# CBASS_AC_NONSAFE0_QOS register map
Vendor: Texas Instruments
Peripheral module from a debugger description file (folder J721S2).
Registers are 32-bit, read-write, reset 0x7000 unless marked. A register's access mark holds for its fields unless they carry their own. Offsets are as the file gives them; lines under a group give offsets from that group; [hi:lo] are bit positions; {n}, {i} and the like mark numbered series; 'fields as' and 'values as' point back to an identical list; <NAME> marks a mode.

## CBASS_AC_NONSAFE0_QOS
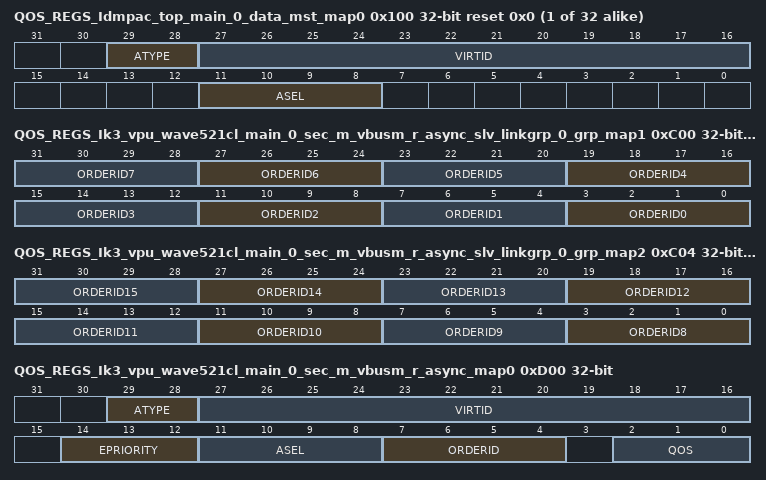
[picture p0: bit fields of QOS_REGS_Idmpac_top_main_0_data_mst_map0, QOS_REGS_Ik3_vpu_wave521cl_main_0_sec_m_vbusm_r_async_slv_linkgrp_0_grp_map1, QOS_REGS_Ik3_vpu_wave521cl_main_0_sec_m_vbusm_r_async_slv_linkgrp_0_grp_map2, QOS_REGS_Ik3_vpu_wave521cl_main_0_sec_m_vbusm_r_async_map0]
{0x100+4i} QOS_REGS_Idmpac_top_main_0_data_mst_map{i} reset 0x0 (i=0..31) — The Map Register defines the fields for the master Idmpac_top_main_0.data_mst per channel.
  [29:28] ATYPE — epriority signal for channel N. 0 = physical. 1 = intermediate. 2 = virtual. 3 = physical with coherence.
  [27:16] VIRTID — virtid signal for channel N.
  [11:8] ASEL — asel signal for channel N. 0 = SOC address. 1-15 = peripheral address.
0xC00 QOS_REGS_Ik3_vpu_wave521cl_main_0_sec_m_vbusm_r_async_slv_linkgrp_0_grp_map1 reset 0x0 — The Group Map Register defines the final orderid for the master Ik3_vpu_wave521cl_main_0.sec_m_vbusm_r_async for group slv_linkgrp_0.
  [4n+3:4n] ORDERID{n} (n=0..7) — orderid signal for {n}.
0xC04 QOS_REGS_Ik3_vpu_wave521cl_main_0_sec_m_vbusm_r_async_slv_linkgrp_0_grp_map2 reset 0x0 — The Group Map Register defines the final orderid for the master Ik3_vpu_wave521cl_main_0.sec_m_vbusm_r_async for group slv_linkgrp_0.
  [4n-29:4n-32] ORDERID{n} (n=8..15) — orderid signal for {n-8}.
0xD00 QOS_REGS_Ik3_vpu_wave521cl_main_0_sec_m_vbusm_r_async_map0 — The Map Register defines the fields for the master Ik3_vpu_wave521cl_main_0.sec_m_vbusm_r_async per channel.
  [29:28] ATYPE — epriority signal for channel N. 0 = physical. 1 = intermediate. 2 = virtual. 3 = physical with coherence.
  [27:16] VIRTID — virtid signal for channel N.
  [14:12] EPRIORITY — epriority signal for channel N.
  [11:8] ASEL — asel signal for channel N. 0 = SOC address. 1-15 = peripheral address.
  [7:4] ORDERID — orderid signal for channel N.
  [2:0] QOS — qos signal for channel N.
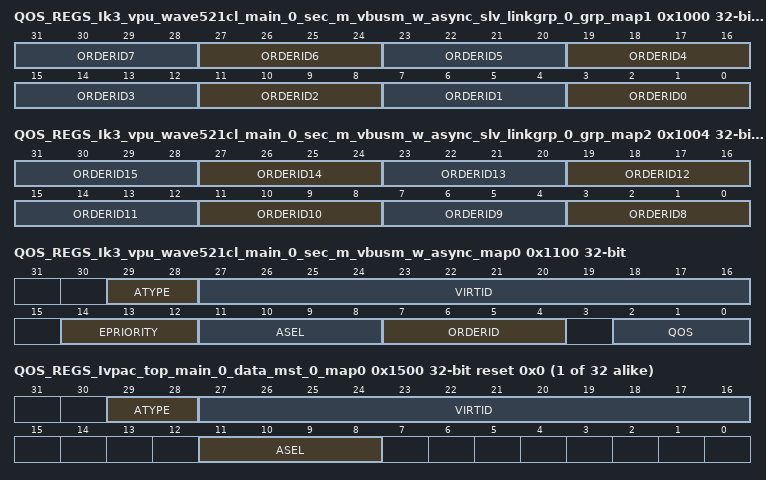
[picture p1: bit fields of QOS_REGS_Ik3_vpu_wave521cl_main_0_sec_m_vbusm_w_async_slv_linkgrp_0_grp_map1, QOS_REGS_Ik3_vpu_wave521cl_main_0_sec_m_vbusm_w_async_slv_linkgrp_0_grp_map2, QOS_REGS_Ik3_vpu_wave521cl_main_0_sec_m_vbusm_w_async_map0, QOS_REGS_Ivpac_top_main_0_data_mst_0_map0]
0x1000 QOS_REGS_Ik3_vpu_wave521cl_main_0_sec_m_vbusm_w_async_slv_linkgrp_0_grp_map1 reset 0x0 — The Group Map Register defines the final orderid for the master Ik3_vpu_wave521cl_main_0.sec_m_vbusm_w_async for group slv_linkgrp_0.
  [4n+3:4n] ORDERID{n} (n=0..7) — orderid signal for {n}.
0x1004 QOS_REGS_Ik3_vpu_wave521cl_main_0_sec_m_vbusm_w_async_slv_linkgrp_0_grp_map2 reset 0x0 — The Group Map Register defines the final orderid for the master Ik3_vpu_wave521cl_main_0.sec_m_vbusm_w_async for group slv_linkgrp_0.
  [4n-29:4n-32] ORDERID{n} (n=8..15) — orderid signal for {n-8}.
0x1100 QOS_REGS_Ik3_vpu_wave521cl_main_0_sec_m_vbusm_w_async_map0 — The Map Register defines the fields for the master Ik3_vpu_wave521cl_main_0.sec_m_vbusm_w_async per channel.
  fields as QOS_REGS_Ik3_vpu_wave521cl_main_0_sec_m_vbusm_r_async_map0
{0x1500+4i} QOS_REGS_Ivpac_top_main_0_data_mst_0_map{i} reset 0x0 (i=0..31) — The Map Register defines the fields for the master Ivpac_top_main_0.data_mst_0 per channel.
  fields as QOS_REGS_Idmpac_top_main_0_data_mst_map0
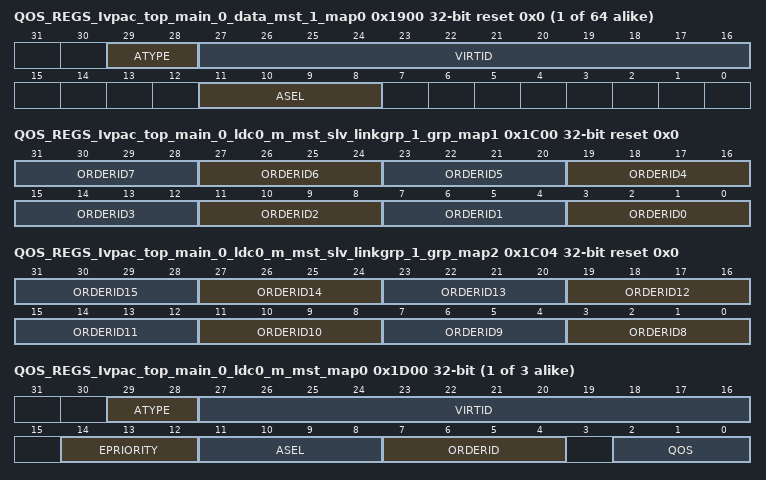
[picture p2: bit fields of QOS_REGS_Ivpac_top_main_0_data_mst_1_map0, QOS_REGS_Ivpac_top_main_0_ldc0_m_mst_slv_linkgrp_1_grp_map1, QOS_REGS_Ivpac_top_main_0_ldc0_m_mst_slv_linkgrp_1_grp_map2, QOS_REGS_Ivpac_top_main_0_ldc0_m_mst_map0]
{0x1900+4i} QOS_REGS_Ivpac_top_main_0_data_mst_1_map{i} reset 0x0 (i=0..63) — The Map Register defines the fields for the master Ivpac_top_main_0.data_mst_1 per channel.
  fields as QOS_REGS_Idmpac_top_main_0_data_mst_map0
0x1C00 QOS_REGS_Ivpac_top_main_0_ldc0_m_mst_slv_linkgrp_1_grp_map1 reset 0x0 — The Group Map Register defines the final orderid for the master Ivpac_top_main_0.ldc0_m_mst for group slv_linkgrp_1.
  [4n+3:4n] ORDERID{n} (n=0..7) — orderid signal for {n}.
0x1C04 QOS_REGS_Ivpac_top_main_0_ldc0_m_mst_slv_linkgrp_1_grp_map2 reset 0x0 — The Group Map Register defines the final orderid for the master Ivpac_top_main_0.ldc0_m_mst for group slv_linkgrp_1.
  [4n-29:4n-32] ORDERID{n} (n=8..15) — orderid signal for {n-8}.
{0x1D00+4i} QOS_REGS_Ivpac_top_main_0_ldc0_m_mst_map{i} (i=0..2) — The Map Register defines the fields for the master Ivpac_top_main_0.ldc0_m_mst per channel.
  fields as QOS_REGS_Ik3_vpu_wave521cl_main_0_sec_m_vbusm_r_async_map0
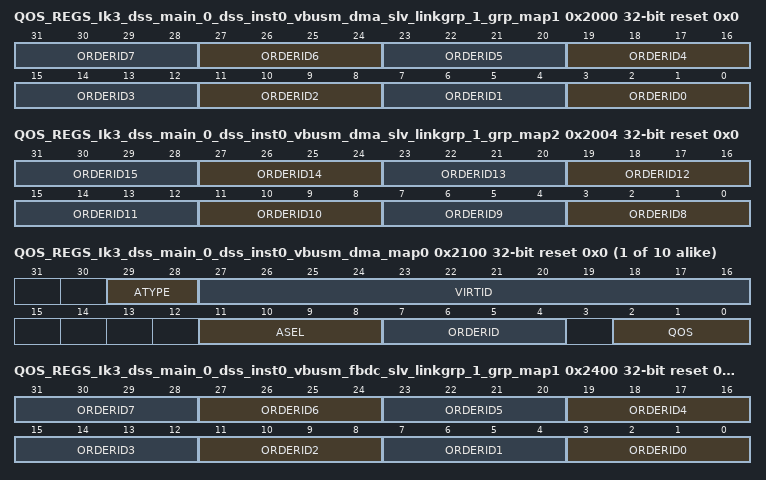
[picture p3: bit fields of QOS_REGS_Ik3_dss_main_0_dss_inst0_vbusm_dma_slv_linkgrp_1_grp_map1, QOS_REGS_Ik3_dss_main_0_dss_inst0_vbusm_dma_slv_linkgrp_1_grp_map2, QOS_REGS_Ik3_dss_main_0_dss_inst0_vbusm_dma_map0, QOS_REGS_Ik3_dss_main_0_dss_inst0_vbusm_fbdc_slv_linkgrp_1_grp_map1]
0x2000 QOS_REGS_Ik3_dss_main_0_dss_inst0_vbusm_dma_slv_linkgrp_1_grp_map1 reset 0x0 — The Group Map Register defines the final orderid for the master Ik3_dss_main_0.dss_inst0_vbusm_dma for group slv_linkgrp_1.
  [4n+3:4n] ORDERID{n} (n=0..7) — orderid signal for {n}.
0x2004 QOS_REGS_Ik3_dss_main_0_dss_inst0_vbusm_dma_slv_linkgrp_1_grp_map2 reset 0x0 — The Group Map Register defines the final orderid for the master Ik3_dss_main_0.dss_inst0_vbusm_dma for group slv_linkgrp_1.
  [4n-29:4n-32] ORDERID{n} (n=8..15) — orderid signal for {n-8}.
{0x2100+4i} QOS_REGS_Ik3_dss_main_0_dss_inst0_vbusm_dma_map{i} reset 0x0 (i=0..9) — The Map Register defines the fields for the master Ik3_dss_main_0.dss_inst0_vbusm_dma per channel.
  [29:28] ATYPE — epriority signal for channel N. 0 = physical. 1 = intermediate. 2 = virtual. 3 = physical with coherence.
  [27:16] VIRTID — virtid signal for channel N.
  [11:8] ASEL — asel signal for channel N. 0 = SOC address. 1-15 = peripheral address.
  [7:4] ORDERID — orderid signal for channel N.
  [2:0] QOS — qos signal for channel N.
0x2400 QOS_REGS_Ik3_dss_main_0_dss_inst0_vbusm_fbdc_slv_linkgrp_1_grp_map1 reset 0x0 — The Group Map Register defines the final orderid for the master Ik3_dss_main_0.dss_inst0_vbusm_fbdc for group slv_linkgrp_1.
  [4n+3:4n] ORDERID{n} (n=0..7) — orderid signal for {n}.
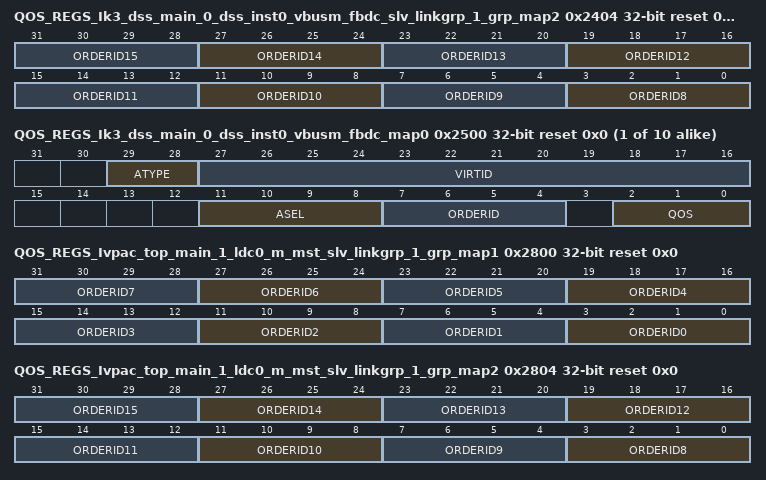
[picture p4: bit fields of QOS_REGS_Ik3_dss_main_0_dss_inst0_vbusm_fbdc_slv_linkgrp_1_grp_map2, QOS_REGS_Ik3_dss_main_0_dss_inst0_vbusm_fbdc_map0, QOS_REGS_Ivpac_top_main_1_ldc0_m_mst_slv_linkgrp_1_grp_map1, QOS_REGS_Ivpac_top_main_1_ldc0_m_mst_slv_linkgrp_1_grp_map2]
0x2404 QOS_REGS_Ik3_dss_main_0_dss_inst0_vbusm_fbdc_slv_linkgrp_1_grp_map2 reset 0x0 — The Group Map Register defines the final orderid for the master Ik3_dss_main_0.dss_inst0_vbusm_fbdc for group slv_linkgrp_1.
  [4n-29:4n-32] ORDERID{n} (n=8..15) — orderid signal for {n-8}.
{0x2500+4i} QOS_REGS_Ik3_dss_main_0_dss_inst0_vbusm_fbdc_map{i} reset 0x0 (i=0..9) — The Map Register defines the fields for the master Ik3_dss_main_0.dss_inst0_vbusm_fbdc per channel.
  fields as QOS_REGS_Ik3_dss_main_0_dss_inst0_vbusm_dma_map0
0x2800 QOS_REGS_Ivpac_top_main_1_ldc0_m_mst_slv_linkgrp_1_grp_map1 reset 0x0 — The Group Map Register defines the final orderid for the master Ivpac_top_main_1.ldc0_m_mst for group slv_linkgrp_1.
  [4n+3:4n] ORDERID{n} (n=0..7) — orderid signal for {n}.
0x2804 QOS_REGS_Ivpac_top_main_1_ldc0_m_mst_slv_linkgrp_1_grp_map2 reset 0x0 — The Group Map Register defines the final orderid for the master Ivpac_top_main_1.ldc0_m_mst for group slv_linkgrp_1.
  [4n-29:4n-32] ORDERID{n} (n=8..15) — orderid signal for {n-8}.
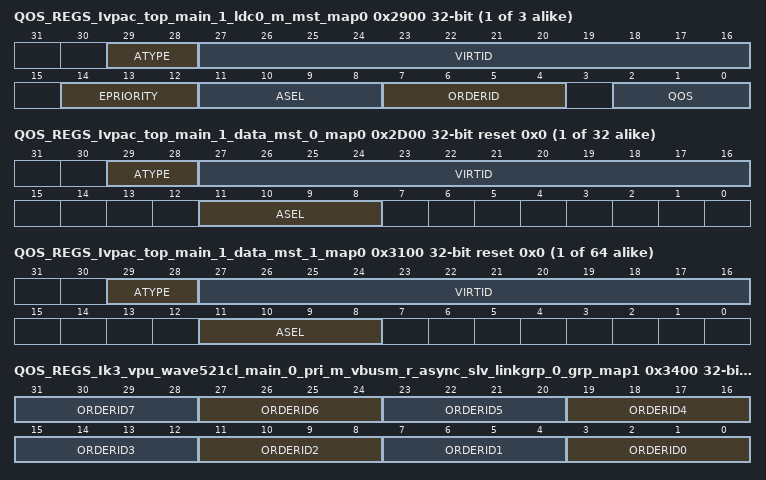
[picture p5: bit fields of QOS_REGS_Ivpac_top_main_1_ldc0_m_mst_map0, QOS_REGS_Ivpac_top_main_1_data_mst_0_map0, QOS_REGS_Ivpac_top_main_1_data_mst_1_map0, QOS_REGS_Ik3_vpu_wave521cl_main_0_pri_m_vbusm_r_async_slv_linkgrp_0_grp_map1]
{0x2900+4i} QOS_REGS_Ivpac_top_main_1_ldc0_m_mst_map{i} (i=0..2) — The Map Register defines the fields for the master Ivpac_top_main_1.ldc0_m_mst per channel.
  fields as QOS_REGS_Ik3_vpu_wave521cl_main_0_sec_m_vbusm_r_async_map0
{0x2D00+4i} QOS_REGS_Ivpac_top_main_1_data_mst_0_map{i} reset 0x0 (i=0..31) — The Map Register defines the fields for the master Ivpac_top_main_1.data_mst_0 per channel.
  fields as QOS_REGS_Idmpac_top_main_0_data_mst_map0
{0x3100+4i} QOS_REGS_Ivpac_top_main_1_data_mst_1_map{i} reset 0x0 (i=0..63) — The Map Register defines the fields for the master Ivpac_top_main_1.data_mst_1 per channel.
  fields as QOS_REGS_Idmpac_top_main_0_data_mst_map0
0x3400 QOS_REGS_Ik3_vpu_wave521cl_main_0_pri_m_vbusm_r_async_slv_linkgrp_0_grp_map1 reset 0x0 — The Group Map Register defines the final orderid for the master Ik3_vpu_wave521cl_main_0.pri_m_vbusm_r_async for group slv_linkgrp_0.
  [4n+3:4n] ORDERID{n} (n=0..7) — orderid signal for {n}.
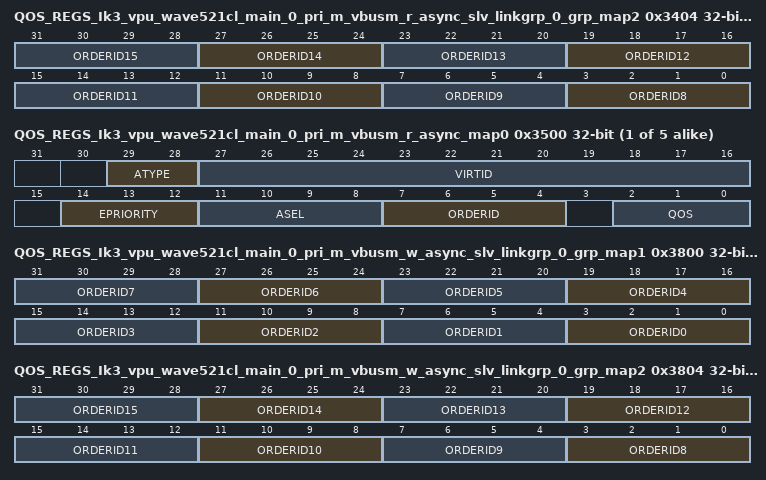
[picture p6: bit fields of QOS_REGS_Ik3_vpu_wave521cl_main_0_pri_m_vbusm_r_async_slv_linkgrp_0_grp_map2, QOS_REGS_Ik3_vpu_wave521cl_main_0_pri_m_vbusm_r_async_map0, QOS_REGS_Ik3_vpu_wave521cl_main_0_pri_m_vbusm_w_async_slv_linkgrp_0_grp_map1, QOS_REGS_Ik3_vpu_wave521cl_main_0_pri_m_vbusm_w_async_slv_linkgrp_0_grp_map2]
0x3404 QOS_REGS_Ik3_vpu_wave521cl_main_0_pri_m_vbusm_r_async_slv_linkgrp_0_grp_map2 reset 0x0 — The Group Map Register defines the final orderid for the master Ik3_vpu_wave521cl_main_0.pri_m_vbusm_r_async for group slv_linkgrp_0.
  [4n-29:4n-32] ORDERID{n} (n=8..15) — orderid signal for {n-8}.
{0x3500+4i} QOS_REGS_Ik3_vpu_wave521cl_main_0_pri_m_vbusm_r_async_map{i} (i=0..4) — The Map Register defines the fields for the master Ik3_vpu_wave521cl_main_0.pri_m_vbusm_r_async per channel.
  fields as QOS_REGS_Ik3_vpu_wave521cl_main_0_sec_m_vbusm_r_async_map0
0x3800 QOS_REGS_Ik3_vpu_wave521cl_main_0_pri_m_vbusm_w_async_slv_linkgrp_0_grp_map1 reset 0x0 — The Group Map Register defines the final orderid for the master Ik3_vpu_wave521cl_main_0.pri_m_vbusm_w_async for group slv_linkgrp_0.
  [4n+3:4n] ORDERID{n} (n=0..7) — orderid signal for {n}.
0x3804 QOS_REGS_Ik3_vpu_wave521cl_main_0_pri_m_vbusm_w_async_slv_linkgrp_0_grp_map2 reset 0x0 — The Group Map Register defines the final orderid for the master Ik3_vpu_wave521cl_main_0.pri_m_vbusm_w_async for group slv_linkgrp_0.
  [4n-29:4n-32] ORDERID{n} (n=8..15) — orderid signal for {n-8}.
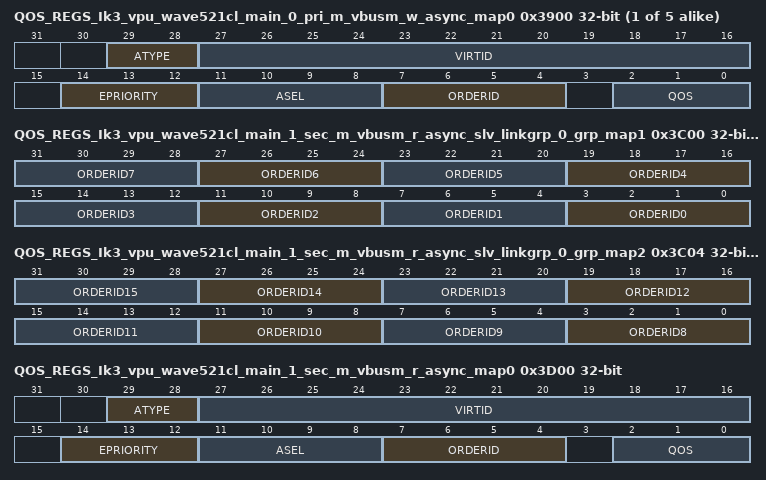
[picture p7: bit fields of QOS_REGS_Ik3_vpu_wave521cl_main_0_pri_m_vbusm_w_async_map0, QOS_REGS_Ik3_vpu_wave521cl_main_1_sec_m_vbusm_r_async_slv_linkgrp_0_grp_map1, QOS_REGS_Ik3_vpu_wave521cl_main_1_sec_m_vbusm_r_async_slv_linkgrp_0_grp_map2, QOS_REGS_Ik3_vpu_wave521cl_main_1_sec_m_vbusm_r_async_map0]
{0x3900+4i} QOS_REGS_Ik3_vpu_wave521cl_main_0_pri_m_vbusm_w_async_map{i} (i=0..4) — The Map Register defines the fields for the master Ik3_vpu_wave521cl_main_0.pri_m_vbusm_w_async per channel.
  fields as QOS_REGS_Ik3_vpu_wave521cl_main_0_sec_m_vbusm_r_async_map0
0x3C00 QOS_REGS_Ik3_vpu_wave521cl_main_1_sec_m_vbusm_r_async_slv_linkgrp_0_grp_map1 reset 0x0 — The Group Map Register defines the final orderid for the master Ik3_vpu_wave521cl_main_1.sec_m_vbusm_r_async for group slv_linkgrp_0.
  [4n+3:4n] ORDERID{n} (n=0..7) — orderid signal for {n}.
0x3C04 QOS_REGS_Ik3_vpu_wave521cl_main_1_sec_m_vbusm_r_async_slv_linkgrp_0_grp_map2 reset 0x0 — The Group Map Register defines the final orderid for the master Ik3_vpu_wave521cl_main_1.sec_m_vbusm_r_async for group slv_linkgrp_0.
  [4n-29:4n-32] ORDERID{n} (n=8..15) — orderid signal for {n-8}.
0x3D00 QOS_REGS_Ik3_vpu_wave521cl_main_1_sec_m_vbusm_r_async_map0 — The Map Register defines the fields for the master Ik3_vpu_wave521cl_main_1.sec_m_vbusm_r_async per channel.
  fields as QOS_REGS_Ik3_vpu_wave521cl_main_0_sec_m_vbusm_r_async_map0
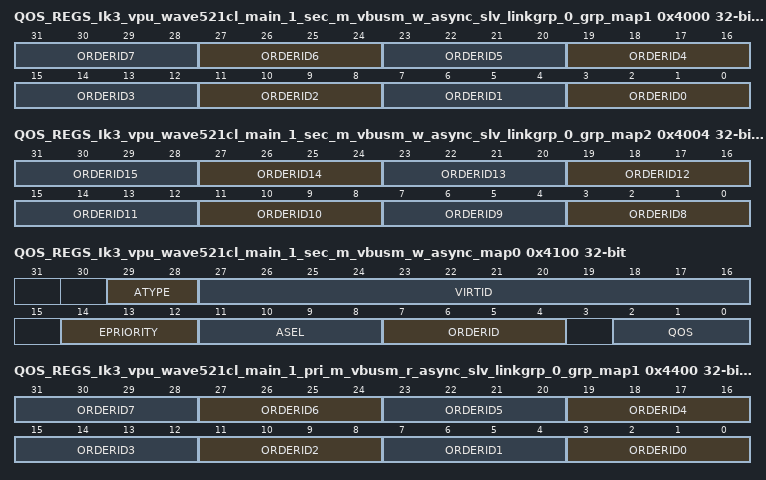
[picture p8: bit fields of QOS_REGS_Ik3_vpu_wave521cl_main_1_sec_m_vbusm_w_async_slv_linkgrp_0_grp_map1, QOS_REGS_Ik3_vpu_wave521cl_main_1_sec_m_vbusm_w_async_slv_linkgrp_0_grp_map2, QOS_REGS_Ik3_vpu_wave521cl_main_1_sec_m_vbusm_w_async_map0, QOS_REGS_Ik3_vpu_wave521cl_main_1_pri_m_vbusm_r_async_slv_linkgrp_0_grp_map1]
0x4000 QOS_REGS_Ik3_vpu_wave521cl_main_1_sec_m_vbusm_w_async_slv_linkgrp_0_grp_map1 reset 0x0 — The Group Map Register defines the final orderid for the master Ik3_vpu_wave521cl_main_1.sec_m_vbusm_w_async for group slv_linkgrp_0.
  [4n+3:4n] ORDERID{n} (n=0..7) — orderid signal for {n}.
0x4004 QOS_REGS_Ik3_vpu_wave521cl_main_1_sec_m_vbusm_w_async_slv_linkgrp_0_grp_map2 reset 0x0 — The Group Map Register defines the final orderid for the master Ik3_vpu_wave521cl_main_1.sec_m_vbusm_w_async for group slv_linkgrp_0.
  [4n-29:4n-32] ORDERID{n} (n=8..15) — orderid signal for {n-8}.
0x4100 QOS_REGS_Ik3_vpu_wave521cl_main_1_sec_m_vbusm_w_async_map0 — The Map Register defines the fields for the master Ik3_vpu_wave521cl_main_1.sec_m_vbusm_w_async per channel.
  fields as QOS_REGS_Ik3_vpu_wave521cl_main_0_sec_m_vbusm_r_async_map0
0x4400 QOS_REGS_Ik3_vpu_wave521cl_main_1_pri_m_vbusm_r_async_slv_linkgrp_0_grp_map1 reset 0x0 — The Group Map Register defines the final orderid for the master Ik3_vpu_wave521cl_main_1.pri_m_vbusm_r_async for group slv_linkgrp_0.
  [4n+3:4n] ORDERID{n} (n=0..7) — orderid signal for {n}.
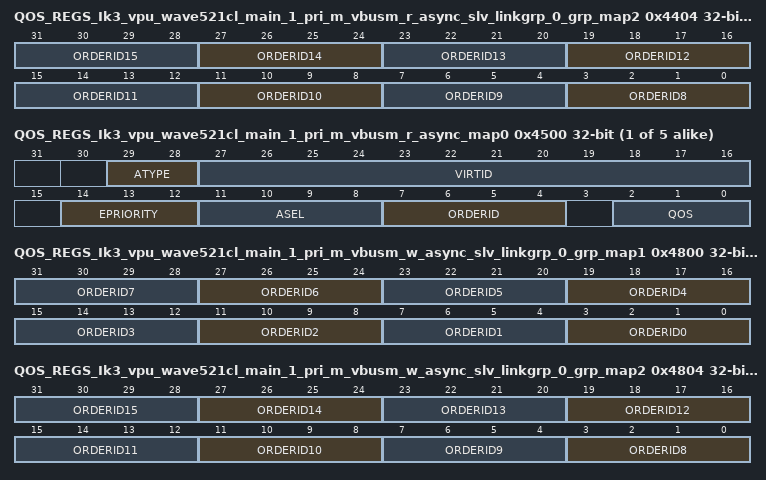
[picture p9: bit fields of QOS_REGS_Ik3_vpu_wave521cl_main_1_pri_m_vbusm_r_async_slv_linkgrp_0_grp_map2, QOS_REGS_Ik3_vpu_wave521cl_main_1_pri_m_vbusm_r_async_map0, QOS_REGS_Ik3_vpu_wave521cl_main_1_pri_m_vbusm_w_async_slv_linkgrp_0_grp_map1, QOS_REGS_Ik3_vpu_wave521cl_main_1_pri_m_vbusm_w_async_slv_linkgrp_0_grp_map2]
0x4404 QOS_REGS_Ik3_vpu_wave521cl_main_1_pri_m_vbusm_r_async_slv_linkgrp_0_grp_map2 reset 0x0 — The Group Map Register defines the final orderid for the master Ik3_vpu_wave521cl_main_1.pri_m_vbusm_r_async for group slv_linkgrp_0.
  [4n-29:4n-32] ORDERID{n} (n=8..15) — orderid signal for {n-8}.
{0x4500+4i} QOS_REGS_Ik3_vpu_wave521cl_main_1_pri_m_vbusm_r_async_map{i} (i=0..4) — The Map Register defines the fields for the master Ik3_vpu_wave521cl_main_1.pri_m_vbusm_r_async per channel.
  fields as QOS_REGS_Ik3_vpu_wave521cl_main_0_sec_m_vbusm_r_async_map0
0x4800 QOS_REGS_Ik3_vpu_wave521cl_main_1_pri_m_vbusm_w_async_slv_linkgrp_0_grp_map1 reset 0x0 — The Group Map Register defines the final orderid for the master Ik3_vpu_wave521cl_main_1.pri_m_vbusm_w_async for group slv_linkgrp_0.
  [4n+3:4n] ORDERID{n} (n=0..7) — orderid signal for {n}.
0x4804 QOS_REGS_Ik3_vpu_wave521cl_main_1_pri_m_vbusm_w_async_slv_linkgrp_0_grp_map2 reset 0x0 — The Group Map Register defines the final orderid for the master Ik3_vpu_wave521cl_main_1.pri_m_vbusm_w_async for group slv_linkgrp_0.
  [4n-29:4n-32] ORDERID{n} (n=8..15) — orderid signal for {n-8}.
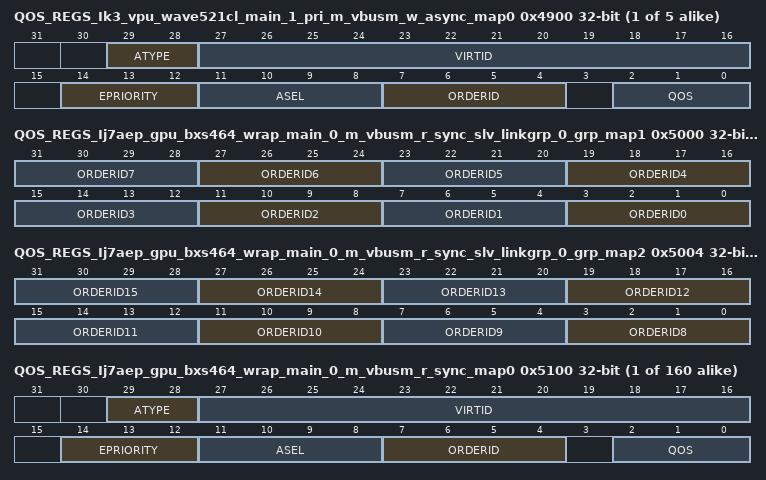
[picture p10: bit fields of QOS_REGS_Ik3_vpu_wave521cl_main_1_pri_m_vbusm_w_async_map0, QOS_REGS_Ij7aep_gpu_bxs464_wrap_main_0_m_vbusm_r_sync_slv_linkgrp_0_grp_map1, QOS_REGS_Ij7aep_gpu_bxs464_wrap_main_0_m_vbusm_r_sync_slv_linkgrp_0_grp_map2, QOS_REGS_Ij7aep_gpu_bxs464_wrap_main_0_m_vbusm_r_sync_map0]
{0x4900+4i} QOS_REGS_Ik3_vpu_wave521cl_main_1_pri_m_vbusm_w_async_map{i} (i=0..4) — The Map Register defines the fields for the master Ik3_vpu_wave521cl_main_1.pri_m_vbusm_w_async per channel.
  fields as QOS_REGS_Ik3_vpu_wave521cl_main_0_sec_m_vbusm_r_async_map0
0x5000 QOS_REGS_Ij7aep_gpu_bxs464_wrap_main_0_m_vbusm_r_sync_slv_linkgrp_0_grp_map1 reset 0x0 — The Group Map Register defines the final orderid for the master Ij7aep_gpu_bxs464_wrap_main_0.m_vbusm_r_sync for group slv_linkgrp_0.
  [4n+3:4n] ORDERID{n} (n=0..7) — orderid signal for {n}.
0x5004 QOS_REGS_Ij7aep_gpu_bxs464_wrap_main_0_m_vbusm_r_sync_slv_linkgrp_0_grp_map2 reset 0x0 — The Group Map Register defines the final orderid for the master Ij7aep_gpu_bxs464_wrap_main_0.m_vbusm_r_sync for group slv_linkgrp_0.
  [4n-29:4n-32] ORDERID{n} (n=8..15) — orderid signal for {n-8}.
{0x5100+4i} QOS_REGS_Ij7aep_gpu_bxs464_wrap_main_0_m_vbusm_r_sync_map{i} (i=0..159) — The Map Register defines the fields for the master Ij7aep_gpu_bxs464_wrap_main_0.m_vbusm_r_sync per channel.
  fields as QOS_REGS_Ik3_vpu_wave521cl_main_0_sec_m_vbusm_r_async_map0
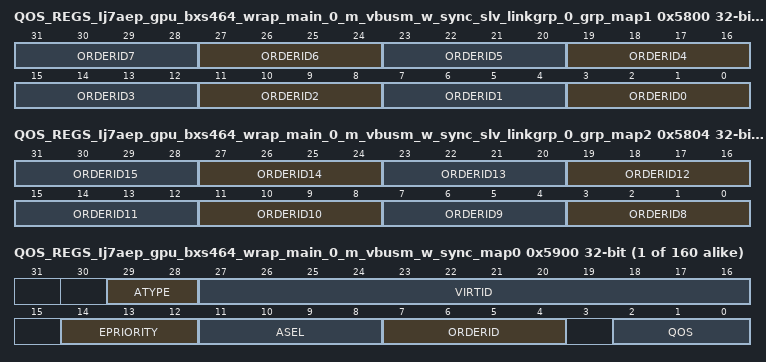
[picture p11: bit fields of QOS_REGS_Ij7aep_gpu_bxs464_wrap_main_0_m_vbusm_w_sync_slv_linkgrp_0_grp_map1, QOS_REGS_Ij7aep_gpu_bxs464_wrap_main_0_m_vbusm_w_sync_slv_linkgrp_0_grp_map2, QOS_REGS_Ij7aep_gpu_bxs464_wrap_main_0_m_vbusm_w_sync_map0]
0x5800 QOS_REGS_Ij7aep_gpu_bxs464_wrap_main_0_m_vbusm_w_sync_slv_linkgrp_0_grp_map1 reset 0x0 — The Group Map Register defines the final orderid for the master Ij7aep_gpu_bxs464_wrap_main_0.m_vbusm_w_sync for group slv_linkgrp_0.
  [4n+3:4n] ORDERID{n} (n=0..7) — orderid signal for {n}.
0x5804 QOS_REGS_Ij7aep_gpu_bxs464_wrap_main_0_m_vbusm_w_sync_slv_linkgrp_0_grp_map2 reset 0x0 — The Group Map Register defines the final orderid for the master Ij7aep_gpu_bxs464_wrap_main_0.m_vbusm_w_sync for group slv_linkgrp_0.
  [4n-29:4n-32] ORDERID{n} (n=8..15) — orderid signal for {n-8}.
{0x5900+4i} QOS_REGS_Ij7aep_gpu_bxs464_wrap_main_0_m_vbusm_w_sync_map{i} (i=0..159) — The Map Register defines the fields for the master Ij7aep_gpu_bxs464_wrap_main_0.m_vbusm_w_sync per channel.
  fields as QOS_REGS_Ik3_vpu_wave521cl_main_0_sec_m_vbusm_r_async_map0
